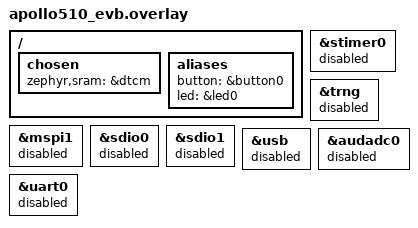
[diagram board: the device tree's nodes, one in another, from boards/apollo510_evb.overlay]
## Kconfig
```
#
# Copyright (c) 2025 Ambiq Micro Inc. <www.ambiq.com>
#
# SPDX-License-Identifier: Apache-2.0
#

menu "Zephyr Kernel"
	source "Kconfig.zephyr"
endmenu

menu "CoreMark sample"

config APP_MODE_FLASH_AND_RUN
	bool "Run CoreMark benchmark on start up"
	help
	  If enabled, CoreMark will start execution immediately after CPU start up.
	  Otherwise, it will wait button to be pressed.

endmenu
```

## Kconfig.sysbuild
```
#
# Copyright (c) 2025 Ambiq Micro Inc. <www.ambiq.com>
#
# SPDX-License-Identifier: Apache-2.0
#

source "share/sysbuild/Kconfig"

config IMAGE_2_BOARD
	string "Second additional board name to build sample for"

config IMAGE_3_BOARD
	string "Third additional board name to build sample for"
```

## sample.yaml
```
sample:
  name: CoreMark Benchmark
  description: CoreMark sample for the CPU performance evaluation.
               Sample runs the CoreMark benchmark that measures the CPU efficiency
               performing  different algorithms like state machine, crc calculation,
               matrix manipulation and list processing (find and sort).
tests:
  sample.benchmark.coremark:
    platform_allow:
      - apollo510_evb
      - apollo510b_evb
    integration_platforms:
      - apollo510_evb
      - apollo510b_evb
    harness: console
    harness_config:
      type: multi_line
      ordered: true
      regex:
        - "Coremark started"
        - "Correct operation validated"
        - "Coremark finished"

  sample.benchmark.coremark.sysbuild:
    platform_allow: nrf52840dk/nrf52840
    extra_args: --sysbuild
    integration_platforms:
      - nrf52840dk/nrf52840
```

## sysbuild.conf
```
SB_CONFIG_IMAGE_2_BOARD="nrf5340dk_nrf5340_cpunet"
```

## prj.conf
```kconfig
# Common coremark configuration
CONFIG_COREMARK=y

CONFIG_PM=y
CONFIG_PM_DEVICE=y
CONFIG_PM_DEVICE_RUNTIME=y

CONFIG_COREMARK_ITERATIONS=4500

# Single thread execution
CONFIG_COREMARK_THREADS_NUMBER=1
# Choose memory method
CONFIG_COREMARK_MEMORY_METHOD_STACK=y
#CONFIG_COREMARK_MEMORY_METHOD_MALLOC=y

# Supported only for single thread. No stack or heap required
#CONFIG_COREMARK_MEMORY_METHOD_STATIC=y

# Choose proper memory size based on memory method selected above
# For 1 thread
CONFIG_MAIN_STACK_SIZE=4096
#CONFIG_HEAP_MEM_POOL_SIZE=4096

# For 4 threads
CONFIG_TIMESLICE_SIZE=10
#CONFIG_MAIN_STACK_SIZE=10240
#CONFIG_HEAP_MEM_POOL_SIZE=10240

# Compiler options
CONFIG_COMPILER_OPT="-O3"

# Config results output
CONFIG_LOG=y
CONFIG_PRINTK=y
CONFIG_CBPRINTF_FP_SUPPORT=y
CONFIG_CONSOLE=y
CONFIG_PRINTK_SYNC=y

CONFIG_GPIO=y

CONFIG_MAIN_THREAD_PRIORITY=-1
```

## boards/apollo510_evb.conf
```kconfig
CONFIG_APP_MODE_FLASH_AND_RUN=y
CONFIG_LOG_MODE_IMMEDIATE=y

CONFIG_SYS_CLOCK_HW_CYCLES_PER_SEC=900
CONFIG_SYS_CLOCK_TICKS_PER_SEC=28

CONFIG_SYS_HEAP_AUTO=n
CONFIG_COMMON_LIBC_MALLOC=n
```

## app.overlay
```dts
/*
 * Copyright (c) 2025 Ambiq Micro Inc. <www.ambiq.com>
 *
 * SPDX-License-Identifier: Apache-2.0
 */

 / {
	aliases {
		button = &button0;
		led = &led0;
	};
 };
```

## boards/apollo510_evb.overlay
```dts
/*
 * Copyright (c) 2025 Ambiq Micro Inc. <www.ambiq.com>
 *
 * SPDX-License-Identifier: Apache-2.0
 */

/ {
	/delete-node/ xo32m_xtal;

	chosen {
		zephyr,sram = &dtcm;
	};

	aliases {
		button = &button0;
		led = &led0;
	};
};

&stimer0 {
	status = "disabled";
};

&trng {
	status = "disabled";
};

&mspi1 {
	status = "disabled";
};

&sdio0 {
	status = "disabled";
};

&sdio1 {
	status = "disabled";
};

zephyr_udc0: &usb {
	status = "disabled";
};

&audadc0 {
	status = "disabled";
};

&uart0 {
	status = "disabled";
};
```

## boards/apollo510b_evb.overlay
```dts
/*
 * Copyright (c) 2025 Ambiq Micro Inc. <www.ambiq.com>
 *
 * SPDX-License-Identifier: Apache-2.0
 */

/ {
	/delete-node/ xo32m_xtal;

	chosen {
		zephyr,sram = &dtcm;
	};

	aliases {
		button = &button0;
		led = &led0;
	};
};

&stimer0 {
	clk-source = <6>;
};

&trng {
	status = "disabled";
};

&mspi1 {
	status = "disabled";
};

&sdio0 {
	status = "disabled";
};

&sdio1 {
	status = "disabled";
};

zephyr_udc0: &usb {
	status = "disabled";
};

&audadc0 {
	status = "disabled";
};

&uart0 {
	zephyr,pm-device-runtime-auto;
};
```

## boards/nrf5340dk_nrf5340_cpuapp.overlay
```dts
/*
 * Copyright (c) 2023 Nordic Semiconductor ASA
 *
 * SPDX-License-Identifier: Apache-2.0
 */

 #include "../app.overlay"

 / {
	gpio_fwd: nrf-gpio-forwarder {
		compatible = "nordic,nrf-gpio-forwarder";
		status = "okay";
			button_1 {
				gpios = < &gpio0 0x18 0x11 >;
		};
	};

	gpio_fwd: nrf-gpio-forwarder {
		compatible = "nordic,nrf-gpio-forwarder";
		status = "okay";
			led_1 {
				gpios = < &gpio0 0x1d 0x1 >;
		};
	};
 };
```

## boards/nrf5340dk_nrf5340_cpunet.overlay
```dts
/*
 * Copyright (c) 2023 Nordic Semiconductor ASA
 *
 * SPDX-License-Identifier: Apache-2.0
 */

 / {
	aliases {
		button = &button1;
		led = &led1;
	};
 };
```

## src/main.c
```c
/*
 * Copyright (c) 2025, Ambiq Micro, Inc.
 *
 * SPDX-License-Identifier: Apache-2.0
 */

#include <zephyr/kernel.h>
#include <zephyr/logging/log.h>
#include <zephyr/logging/log_ctrl.h>
#include <zephyr/drivers/gpio.h>

#include "coremark_zephyr.h"

LOG_MODULE_REGISTER(app, LOG_LEVEL_INF);

/*
 * Get button and led configuration from the devicetree.
 * Application expects to have button and led aliases present in devicetree.
 */
#if DT_NODE_HAS_STATUS(BUTTON_NODE, okay)
#define BUTTON_NODE  DT_ALIAS(button)
#define BUTTON_LABEL DT_PROP(DT_ALIAS(button), label)
static const struct gpio_dt_spec start_button = GPIO_DT_SPEC_GET(BUTTON_NODE, gpios);
static struct gpio_callback button_cb_data;
#endif

#if DT_NODE_HAS_STATUS(LED_NODE, okay)
#define LED_NODE DT_ALIAS(led)
static const struct gpio_dt_spec status_led = GPIO_DT_SPEC_GET(LED_NODE, gpios);
#endif

static K_SEM_DEFINE(start_coremark, 0, 1);
static bool coremark_in_progress;

static void flush_log(void)
{
	if (IS_ENABLED(CONFIG_LOG_PROCESS_THREAD)) {
		while (log_data_pending()) {
			k_sleep(K_MSEC(10));
		}
		k_sleep(K_MSEC(10));
	} else {
		while (LOG_PROCESS()) {
		}
	}
}

#if DT_NODE_HAS_STATUS(LED_NODE, okay)
static void led_init(void)
{
	int ret;

	if (!device_is_ready(status_led.port)) {
		LOG_INF("Error: led device %s is not ready",
			status_led.port->name);
		return;
	}

	ret = gpio_pin_configure_dt(&status_led, GPIO_OUTPUT_ACTIVE);
	if (ret != 0) {
		LOG_INF("Error %d: failed to configure %s pin %d",
			ret, status_led.port->name, status_led.pin);
		return;
	}

	gpio_pin_set_dt(&status_led, GPIO_ACTIVE_HIGH);
}
#endif

#if DT_NODE_HAS_STATUS(BUTTON_NODE, okay)
static void button_pressed(const struct device *dev, struct gpio_callback *cb, uint32_t pins)
{
	if (gpio_pin_get_dt(&start_button) && !coremark_in_progress) {
		LOG_INF("%s pressed!", BUTTON_LABEL);
		coremark_in_progress = true;
		k_sem_give(&start_coremark);
	}
}

static void button_init(void)
{
	int ret;

	if (!device_is_ready(start_button.port)) {
		LOG_INF("Error: button1 device %s is not ready",
			start_button.port->name);
		return;
	}

	ret = gpio_pin_configure_dt(&start_button, GPIO_INPUT);
	if (ret != 0) {
		LOG_INF("Error %d: failed to configure %s pin %d",
			ret, start_button.port->name, start_button.pin);
		return;
	}

	ret = gpio_pin_interrupt_configure_dt(&start_button, GPIO_INT_EDGE_BOTH);

	if (ret != 0) {
		LOG_INF("Error %d: failed to configure interrupt on %s pin %d",
			ret, start_button.port->name, start_button.pin);
		return;
	}

	gpio_init_callback(&button_cb_data, button_pressed, BIT(start_button.pin));
	gpio_add_callback(start_button.port, &button_cb_data);
}
#endif

int main(void)
{
	LOG_INF("Coremark sample for %s", CONFIG_BOARD);

#if DT_NODE_HAS_STATUS(LED_NODE, okay)
	led_init();
#endif
#if DT_NODE_HAS_STATUS(BUTTON_NODE, okay)
	button_init();
#endif

	if (IS_ENABLED(CONFIG_APP_MODE_FLASH_AND_RUN)) {
		coremark_in_progress = true;
		k_sem_give(&start_coremark);
	} else {
#if DT_NODE_HAS_STATUS(BUTTON_NODE, okay)
		LOG_INF("Press %s to start the test ...", BUTTON_LABEL);
#endif
	}

	while (true) {
		k_sem_take(&start_coremark, K_FOREVER);
		LOG_INF("Coremark started!");
#if defined(CONFIG_SOC_SERIES_APOLLO5X)
		LOG_INF("CPU FREQ: %d Hz", AM_HAL_CLKGEN_FREQ_MAX_HZ);
#endif
		LOG_INF("(threads: %d, data size: %d; iterations: %d)\n",
			CONFIG_COREMARK_THREADS_NUMBER,
			CONFIG_COREMARK_DATA_SIZE,
			CONFIG_COREMARK_ITERATIONS);
		flush_log();

#if DT_NODE_HAS_STATUS(LED_NODE, okay)
		gpio_pin_set_dt(&status_led, GPIO_ACTIVE_LOW);
#endif
		coremark_run();
#if DT_NODE_HAS_STATUS(LED_NODE, okay)
		gpio_pin_set_dt(&status_led, GPIO_ACTIVE_HIGH);
#endif

		LOG_INF("Coremark finished!\n");
#if DT_NODE_HAS_STATUS(BUTTON_NODE, okay)
		LOG_INF("Press %s to restart ...\n", BUTTON_LABEL);
#endif

		coremark_in_progress = false;
	};

	return 0;
}
```
